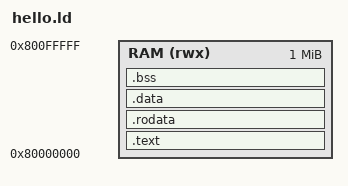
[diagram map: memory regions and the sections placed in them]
OUTPUT_ARCH("riscv")
ENTRY(_start)

MEMORY {
    RAM (rwx) : ORIGIN = 0x80000000, LENGTH = 1M
}

SECTIONS {
    .text : {
        *(.text.start)
        *(.text*)
    } > RAM

    .rodata : {
        *(.rodata*)
    } > RAM

    .data : {
        *(.data*)
    } > RAM

    .bss : {
        . = ALIGN(8);
        __bss_start = .;
        *(.bss*)
        *(.sbss*)
        *(COMMON)
        . = ALIGN(8);
        __bss_end = .;
    } > RAM

    _end = .;
    _stack_top = ORIGIN(RAM) + LENGTH(RAM);
}
